# TLE986x register map
File version: 2.5
Registers are 32-bit, read-write, reset 0x0 unless marked. A register's access mark holds for its fields unless they carry their own. Offsets are from the block's base; [hi:lo] are bit positions; {n}, {i} and the like mark numbered series; 'fields as' and 'values as' point back to an identical list.

## PMU
Base 0x50004000
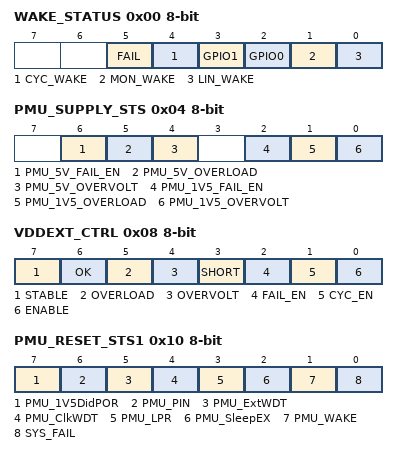
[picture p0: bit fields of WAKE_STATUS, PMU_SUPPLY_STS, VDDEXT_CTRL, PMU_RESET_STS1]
0x00 WAKE_STATUS 8-bit ro (reset mask 0xC0) — Main wake status register
  [all] fields
    0=No Wake-up occurred; 1=Wake-up occurred
  [5] FAIL — Wake-up after VDDEXT Fail
  [4] CYC_WAKE — Wake-up caused by Cyclic Wake
  [3] GPIO1 — Wake-up via GPIO1 which is a logical OR combination of all Wake_STS_GPIO1 bits
  [2] GPIO0 — Wake-up via GPIO0 which is a logical OR combination of all Wake_STS_GPIO0 bits
  [1] MON_WAKE — Wake-up via MON
  [0] LIN_WAKE — Wake-up via LIN- Message
0x04 PMU_SUPPLY_STS 8-bit access per field (reset mask 0xCC) — Voltage Reg Status Register
  [6] PMU_5V_FAIL_EN rw — Enabling of VDDP status information as interrupt source
    0=No interrupts are generated; 1=Interrupts are generated
  [5] PMU_5V_OVERLOAD ro — Overload at VDDP regulator
    0=No overload; 1=Overload
  [4] PMU_5V_OVERVOLT ro — Overvoltage at VDDP regulator
    0=No overvoltage; 1=Overvoltage
  [2] PMU_1V5_FAIL_EN rw — Enabling of VDDC status information as interrupt source
    0=No interrupts are generated; 1=Interrupts are generated
  [1] PMU_1V5_OVERLOAD ro — Overload at VDDC regulator
    0=No overload; 1=Overload
  [0] PMU_1V5_OVERVOLT ro — Overvoltage at VDDC regulator
    0=No overvoltage; 1=Overvoltage
0x08 VDDEXT_CTRL 8-bit access per field (reset mask 0xF) — VDDEXT Control
  [7] STABLE ro — VDDEXT Supply works inside its specified range 1
    1=VDDEXT Voltage inside of specified range; 0=VDDEXT Voltage outside of specified range
  [6] OK ro — VDDEXT Supply works inside its specified range 2
    1=VDDEXT in low drop mode; 0=VDDEXT not in low drop mode
  [5] OVERLOAD rw — VDDEXT Supply Overload
    0=VDDEXT not in overload condition; 1=VDDEXT in overload condition
  [4] OVERVOLT rw — VDDEXT Supply Overvoltage
    0=VDDEXT not in overvoltage condition; 1=VDDEXT in overvoltage condition
  [3] SHORT rw — VDDEXT Supply Shorted Output
    0=VDDEXT no short circuit; 1=VDDEXT short circuit
  [2] FAIL_EN rw — Enabling of VDDEXT Supply status information as interrupt source
    0=VDDEXT fail interrupts are disabled; 1=VDDEXT fail Interrupts are enabled
  [1] CYC_EN rw — VDDEXT Supply for Cyclic Sense Enable
    0=VDDEXT for cyclic sense disable; 1=VDDEXT for cyclic sense enable
  [0] ENABLE rw — VDDEXT Supply Enable
    0=VDDEXT Supply disabled; 1=VDDEXT supply enabled
0x10 PMU_RESET_STS1 8-bit — Reset Status Hard Register
  [7] PMU_1V5DidPOR — Power-On Reset Flag
    0=No Power-On reset executed; 1=Power-On reset executed
  [6] PMU_PIN — PIN-Reset Flag
    0=No PIN-Reset executed; 1=PIN-Reset executed
  [5] PMU_ExtWDT — External Watchdog (WDT1) Reset Flag
    0=No External Watchdog reset executed; 1=External Watchdog reset executed
  [4] PMU_ClkWDT — Clock Watchdog (CLKWDT) Reset Flag
    0=No Clock Watchdog reset executed; 1=Clock Watchdog reset executed
  [3] PMU_LPR — Low Priority Resets (see PMU_RESET_STS2)
    0=Low Priority-Reset executed; 1=Low Priority executed
  [2] PMU_SleepEX — Flag which indicates a reset caused by Sleep-Exit
    0=No reset caused by Sleep-Exit executed; 1=Reset caused by Sleep-Exit executed
  [1] PMU_WAKE — Flag which indicates a reset caused by Stop-Exit
    0=No reset caused by Stop-Exit executed; 1=Reset caused by Stop-Exit executed
  [0] SYS_FAIL — Flag which indicates a reset caused by a System Fail reported in the corresponding Fail Register
    0=No reset caused by System Fail executed; 1=Reset caused by System Fail executed
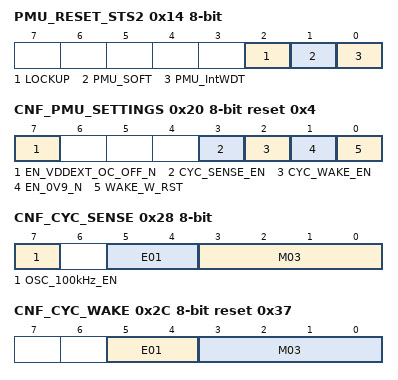
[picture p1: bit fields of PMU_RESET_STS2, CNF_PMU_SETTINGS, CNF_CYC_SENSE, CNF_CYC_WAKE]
0x14 PMU_RESET_STS2 8-bit — Reset Status Soft Register
  [2] LOCKUP — Lockup-Reset Flag
    0=No Lockup-Reset executed; 1=Lockup-Reset executed
  [1] PMU_SOFT — Soft-Reset Flag
    0=No Soft-Reset executed; 1=Soft-Reset executed
  [0] PMU_IntWDT — Internal Watchdog Reset Flag
    0=No Internal Watchdog reset executed; 1=Internal Watchdog reset executed
0x20 CNF_PMU_SETTINGS 8-bit reset 0x4 — PMU Settings Register
  [7] EN_VDDEXT_OC_OFF_N — Disabling VDDEXT Shutdown in Overload Condition
    0=Shutdown enabled; 1=Shutdown disabled
  [3] CYC_SENSE_EN — Enabling Cyclic Sense
    0=Cyclic Sense disabled; 1=Cyclic Sense enabled
  [2] CYC_WAKE_EN — Enabling Cyclic Wake
    0=Cyclic Wake disabled; 1=Cyclic Wake enabled
  [1] EN_0V9_N — Disables the reduction of the VDDC regulator output to 0.9 V during Stop-Mode
    0=Output voltage reduction enabled; 1=Output voltage reduction disabled
  [0] WAKE_W_RST — Wake-up with reset execution
    0=Stop-Exit without reset execution; 1=Stop-Exit with reset execution
0x28 CNF_CYC_SENSE 8-bit — Dead Time in Cyclic Sense Register
  [7] OSC_100kHz_EN — 100 kHz Oscillator Enable
    0=DISABLE (Oscillator is disabled); 1=ENABLE (Oscillator is enabled)
  [5:4] E01 — Exponent
    {v}=Exponent value is {v} (v=0..3)
  [3:0] M03 — Mantissa
    0=Mantissa value is 1; 15=Mantissa value is 16
0x2C CNF_CYC_WAKE 8-bit reset 0x37 — Dead Time in Cyclic Wake Register
  [5:4] E01 — Exponent
    {v}=Exponent value is {v} (v=0..3)
  [3:0] M03 — Mantissa
    0=Mantissa value is 1; 15=Mntissa value is 16
0x30 CNF_CYC_SAMPLE_DEL 8-bit — Sample Delay in Cyclic Sense Register
  [3:0] M03 — Mantissa
    0=variable value M3M2M1M0 is 0; 15=variable value M3M3M1M0 is 15
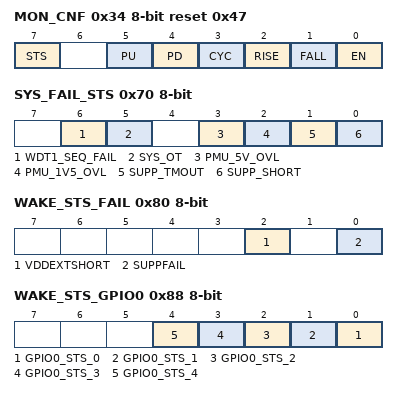
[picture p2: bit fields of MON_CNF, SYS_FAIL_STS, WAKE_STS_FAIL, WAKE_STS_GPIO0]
0x34 MON_CNF 8-bit access per field reset 0x47 — Settings Monitor 1
  [7] STS ro — MON Status Input
    0=MON input has low status; 1=MON input has high status
  [5] PU rw — Pull-Up Current Source for MON Input Enable
    0=Pull-up source disabled; 1=Pull-up source enabled
  [4] PD rw — Pull-Down Current Source for MON Input Enable
    0=Pull-down source disabled; 1=Pull-down source enabled
  [3] CYC rw — MON for Cycle Sense Enable
    0=Cycle Sense disabled; 1=Cycle Sense enabled
  [2] RISE rw — MON Wake-up on Rising Edge Enable
    0=Wake-up disabled; 1=Wake-up enabled
  [1] FALL rw — MON Wake-up on Falling Edge Enable
    0=Wake-up disabled; 1=Wake-up enabled
  [0] EN rw — MON Enable
    0=MON disabled; 1=MON enabled
0x50 LIN_WAKE_EN 8-bit — LIN Wake Enable
  [7] LIN_EN — Lin Wake enable
    0=Disable; 1=Enable
0x6C CNF_RST_TFB 8-bit reset 0x3 — Reset Blind Time Register
  [1:0] RST_TFB — Reset Pin Blind Time Selection Bits
    0=0,5 us typ; 1=1 us typ; 2=5 us typ; 3=31 us typ
0x70 SYS_FAIL_STS 8-bit — System Fail Status Register
  [6] WDT1_SEQ_FAIL — External Watchdog (WDT1) Sequential Fail
    0=No Fail (System working properly); 1=Sequential Watchdog Fail (5 consecutive watchdog fails)
  [5] SYS_OT — System Overtemperature Indication Flag
    0=No Overtemperature (System ok); 1=Overtemperature (System Overtemperature)
  [3] PMU_5V_OVL — VDDP Overload Flag
    0=No Overload (VDDP ok); 1=Overload (VDDP Overload)
  [2] PMU_1V5_OVL — VDDC Overload Flag
    0=No Overload (VDDC ok); 1=Overload (Hall VDDC Overload)
  [1] SUPP_TMOUT — Supply Time Out
    0=Main Supply ok (VDDP or VDDC are in expected range); 1=Main Supply fail (VDDP or VDDC do not have stable operating point)
  [0] SUPP_SHORT — Supply Short
    0=Main Supply ok (VDDP or VDDC are in expected range); 1=Main Supply short (VDDP or VDDC do not have stable operating point)
0x80 WAKE_STS_FAIL 8-bit — Wake Status Fail Register
  [2] VDDEXTSHORT — Stop-Exit due to short circuit at the VDDEXT Supply
    0=No short circuit; 1=Short circuit
  [0] SUPPFAIL — Stop-Exit due to overvoltage at the VDDEXT Supply
    0=No overvoltage; 1=Module suspend enabled
0x84 WAKE_STS_MON 8-bit ro — Wake Source MON Input Register
  [0] WAKE_STS — Status of MON
    0=No wake-up detected; 1=wake-up detected
0x88 WAKE_STS_GPIO0 8-bit ro — Wake Status GPIO 0 Register
  [all] fields
    0=No wake-up detected; 1=wake-up detected
  [n] GPIO0_STS_{n} (n=0..4) — Status of GPIO0_{n}
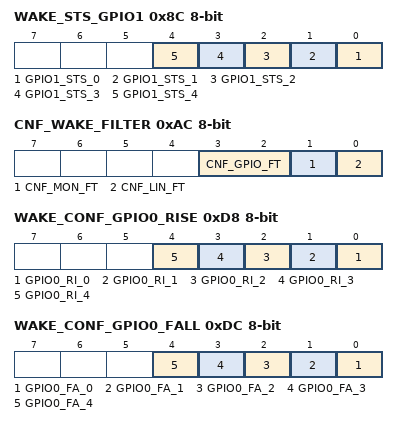
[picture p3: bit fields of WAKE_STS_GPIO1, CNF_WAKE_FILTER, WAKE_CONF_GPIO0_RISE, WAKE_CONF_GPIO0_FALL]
0x8C WAKE_STS_GPIO1 8-bit ro — Wake Status GPIO 1 Register
  [all] fields
    0=No wake-up detected; 1=wake-up detected
  [n] GPIO1_STS_{n} (n=0..4) — Wake GPIO1_{n}
0xAC CNF_WAKE_FILTER 8-bit — PMU Wake-up Timing Register
  [3:2] CNF_GPIO_FT — Wake-up Filter time for General Purpose IO
    0=10 us filter time; 1=20 us filter time; 2=40 us filter time; 3=5 us filter time
  [1] CNF_MON_FT — Wake-up Filter time for Monitoring Inputs
    0=20 us filter time; 1=40 us filter time
  [0] CNF_LIN_FT — Wake-up Filter time for LIN WAKE
    0=30 us filter time; 1=50 us filter time
{0xC0+4i} GPUDATA{i:02} 8-bit (i=0..5) — General Purpose User DATA{i}
  [7:0] DATA{i} — DATA{i} Storage Byte
0xD8 WAKE_CONF_GPIO0_RISE 8-bit — Wake Configuration GPIO Port 0 Rising Edge Register
  [all] fields
    1=ENABLE (wake-up enabled); 0=DISABLE (wake-up disabled)
  [n] GPIO0_RI_{n} (n=0..4) — Port 0_{n} Wake-up on Rising Edge enable
0xDC WAKE_CONF_GPIO0_FALL 8-bit — Wake Configuration GPIO Port 0 Falling Edge Register
  [all] fields
    1=ENABLE (wake-up enabled); 0=DISABLE (wake-up disabled)
  [n] GPIO0_FA_{n} (n=0..4) — Port 0_{n} Wake-up on Falling Edge enable
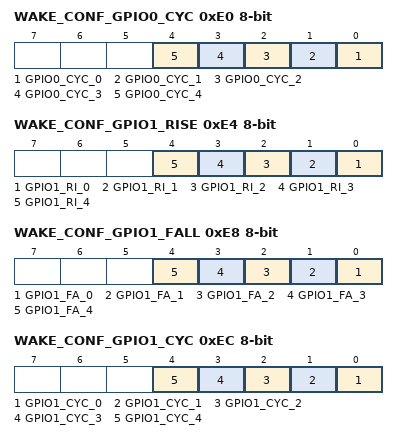
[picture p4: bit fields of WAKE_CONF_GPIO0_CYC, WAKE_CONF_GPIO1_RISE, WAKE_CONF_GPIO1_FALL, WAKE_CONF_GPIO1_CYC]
0xE0 WAKE_CONF_GPIO0_CYC 8-bit — Wake Port 0 Cycle Enabled Register
  [all] fields
    1=ENABLE (input for cycle sense enabled); 0=DISABLE (input for cycle sense disabled)
  [n] GPIO0_CYC_{n} (n=0..4) — GPIO0_{n} input for cycle sense enable
0xE4 WAKE_CONF_GPIO1_RISE 8-bit — Wake Configuration GPIO Port 1 Rising Edge Register
  [all] fields
    1=ENABLE (wake-up enabled); 0=DISABLE (wake-up disabled)
  [n] GPIO1_RI_{n} (n=0..4) — Port 1_{n} Wake-up on Rising Edge enable
0xE8 WAKE_CONF_GPIO1_FALL 8-bit — Wake Configuration GPIO Port 1 Falling Edge Register
  [all] fields
    1=ENABLE (wake-up enabled); 0=DISABLE (wake-up disabled)
  [n] GPIO1_FA_{n} (n=0..4) — Port 1_{n} Wake-up on Falling Edge enable
0xEC WAKE_CONF_GPIO1_CYC 8-bit — Wake Port 1 Cycle Enabled Register
  [all] fields
    values as the fields of WAKE_CONF_GPIO0_CYC
  [n] GPIO1_CYC_{n} (n=0..4) — GPIO1_{n} input for cycle sense enable
0x2D4 SystemStartConfig 8-bit — System Startup Config
  [0] MBIST_EN — System Startup Configuration Bit for RAM MBIST at Sleep Mode exit
    0=No MBIST executed at Sleep Mode exit; 1=MBIST executed at Sleep Mode exit
